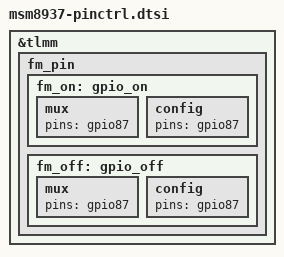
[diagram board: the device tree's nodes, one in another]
&tlmm {
	/delete-node/ spi6;

		fm_pin {
			fm_on: gpio_on {
				mux {
					pins = "gpio87";
				};

				config {
					pins = "gpio87";
				};
			};

			fm_off: gpio_off {
				mux {
					pins = "gpio87";
				};

				config {
					pins = "gpio87";
				};
			};
		};
};
